# SAMA7G54D1G device description
Architecture: CORTEX-A7; Family: SAMA; Series: SAMA7G
Registers are 32-bit, read-write, reset 0x0 unless marked. A register's access mark holds for its fields unless they carry their own. Offsets are from the block's base; [hi:lo] are bit positions; lines under a group give offsets from that group; {n}, {i} and the like mark numbered series; 'fields as' and 'values as' point back to an identical list.

## PWM — Pulse Width Modulation Controller
Instances: PWM 0xE1604000
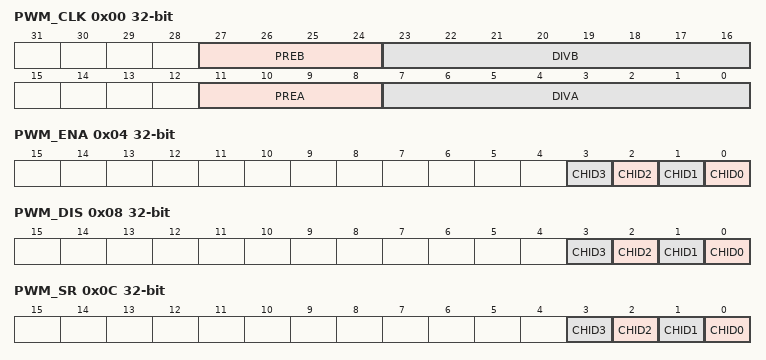
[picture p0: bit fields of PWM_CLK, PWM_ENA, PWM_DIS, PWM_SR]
0x00 PWM_CLK — PWM Clock Register
  [27:24] PREB — CLKB Source Clock Selection
    0=CLK (Peripheral clock); 1=CLK_DIV2 (Peripheral clock/2); 2=CLK_DIV4 (Peripheral clock/4); 3=CLK_DIV8 (Peripheral clock/8); 4=CLK_DIV16 (Peripheral clock/16); 5=CLK_DIV32 (Peripheral clock/32); 6=CLK_DIV64 (Peripheral clock/64); 7=CLK_DIV128 (Peripheral clock/128); 8=CLK_DIV256 (Peripheral clock/256); 9=CLK_DIV512 (Peripheral clock/512); 10=CLK_DIV1024 (Peripheral clock/1024)
  [23:16] DIVB — CLKB Divide Factor
    0=CLKB_POFF (CLKB clock is turned off); 1=PREB (CLKB clock is clock selected by PREB)
  [11:8] PREA — CLKA Source Clock Selection
    values as PREB
  [7:0] DIVA — CLKA Divide Factor
    0=CLKA_POFF (CLKA clock is turned off); 1=PREA (CLKA clock is clock selected by PREA)
0x04 PWM_ENA wo reset not defined — PWM Enable Register
  [all] fields
    0=No effect; 1=Enable PWM output for channel x
  [n] CHID{n} (n=0..3) — Channel ID
0x08 PWM_DIS wo reset not defined (atomic clear of PWM_SR) — PWM Disable Register
  [all] fields
    0=No effect; 1=Disable PWM output for channel x
  [n] CHID{n} (n=0..3) — Channel ID
0x0C PWM_SR ro — PWM Status Register
  [all] fields
    0=PWM output for channel x is disabled; 1=PWM output for channel x is enabled
  [n] CHID{n} (n=0..3) — Channel ID
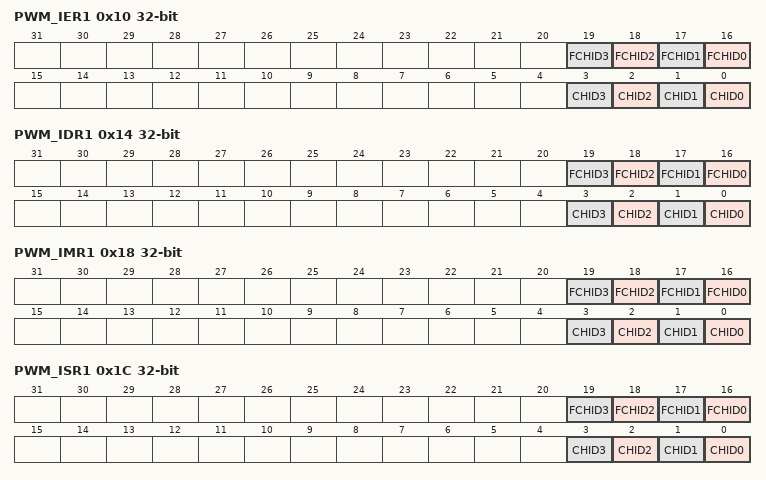
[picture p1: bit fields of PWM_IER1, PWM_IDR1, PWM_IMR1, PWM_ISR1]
0x10 PWM_IER1 wo reset not defined (atomic set of PWM_IMR1) — PWM Interrupt Enable Register 1
  [n+16] FCHID{n} (n=0..3) — Fault Protection Trigger on Channel {n} Interrupt Enable
  [n] CHID{n} (n=0..3) — Counter Event on Channel {n} Interrupt Enable
0x14 PWM_IDR1 wo reset not defined (atomic clear of PWM_IMR1) — PWM Interrupt Disable Register 1
  [n+16] FCHID{n} (n=0..3) — Fault Protection Trigger on Channel {n} Interrupt Disable
  [n] CHID{n} (n=0..3) — Counter Event on Channel {n} Interrupt Disable
0x18 PWM_IMR1 ro — PWM Interrupt Mask Register 1
  [n+16] FCHID{n} (n=0..3) — Fault Protection Trigger on Channel {n} Interrupt Mask
  [n] CHID{n} (n=0..3) — Counter Event on Channel {n} Interrupt Mask
0x1C PWM_ISR1 ro — PWM Interrupt Status Register 1
  [n+16] FCHID{n} (n=0..3) — Fault Protection Trigger on Channel {n}
    0=No new trigger of the fault protection since the last read of PWM_ISR1; 1=At least one trigger of the fault protection since the last read of PWM_ISR1
  [n] CHID{n} (n=0..3) — Counter Event on Channel {n}
    0=No new counter event has occurred since the last read of PWM_ISR1; 1=At least one counter event has occurred since the last read of PWM_ISR1
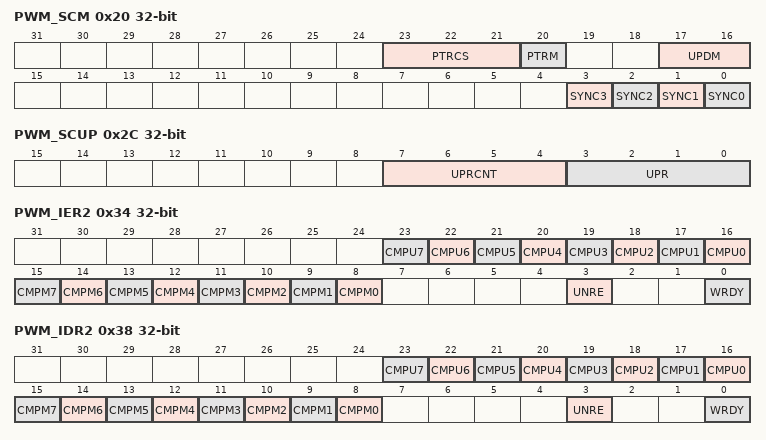
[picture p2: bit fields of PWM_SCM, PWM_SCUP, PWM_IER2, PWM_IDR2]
0x20 PWM_SCM — PWM Sync Channels Mode Register
  [23:21] PTRCS — DMA Controller Transfer Request Comparison Selection
  [20] PTRM — DMA Controller Transfer Request Mode
  [17:16] UPDM — Synchronous Channels Update Mode
    0=MODE0 (Manual write of double buffer registers and manual update of synchronous channels); 1=MODE1 (Manual write of double buffer registers and automatic update of synchronous channels); 2=MODE2 (Automatic write of duty-cycle update registers by the DMA Controller and automatic update of synchronous channels)
  [n] SYNC{n} (n=0..3) — Synchronous Channel {n}
    0=Channel x is not a synchronous channel; 1=Channel x is a synchronous channel
0x24 PWM_DMAR wo reset not defined — PWM DMA Register
  [23:0] DMADUTY — Duty-Cycle Holding Register for DMA Access
0x28 PWM_SCUC — PWM Sync Channels Update Control Register
  [0] UPDULOCK — Synchronous Channels Update Unlock
    0=No effect; 1=If the UPDM field is set to '0' in PWM Sync Channels Mode Register, writing the UPDULOCK bit to '1' triggers the update of the period value, the duty-cycle and the dead-time values of synchronous channels at the beginning of the next PWM period. If the field UPDM is set to '1' or '2', writing the UPDULOCK bit to '1' triggers only the update of the period value and of the dead-time values of synchronous channels.
0x2C PWM_SCUP — PWM Sync Channels Update Period Register
  [7:4] UPRCNT — Update Period Counter
  [3:0] UPR — Update Period
0x30 PWM_SCUPUPD wo reset not defined — PWM Sync Channels Update Period Update Register
  [3:0] UPRUPD — Update Period Update
0x34 PWM_IER2 wo reset not defined (atomic set of PWM_IMR2) — PWM Interrupt Enable Register 2
  [n+16] CMPU{n} (n=0..7) — Comparison {n} Update Interrupt Enable
  [n+8] CMPM{n} (n=0..7) — Comparison {n} Match Interrupt Enable
  [3] UNRE — Synchronous Channels Update Underrun Error Interrupt Enable
  [0] WRDY — Write Ready for Synchronous Channels Update Interrupt Enable
0x38 PWM_IDR2 wo reset not defined (atomic clear of PWM_IMR2) — PWM Interrupt Disable Register 2
  [n+16] CMPU{n} (n=0..7) — Comparison {n} Update Interrupt Disable
  [n+8] CMPM{n} (n=0..7) — Comparison {n} Match Interrupt Disable
  [3] UNRE — Synchronous Channels Update Underrun Error Interrupt Disable
  [0] WRDY — Write Ready for Synchronous Channels Update Interrupt Disable
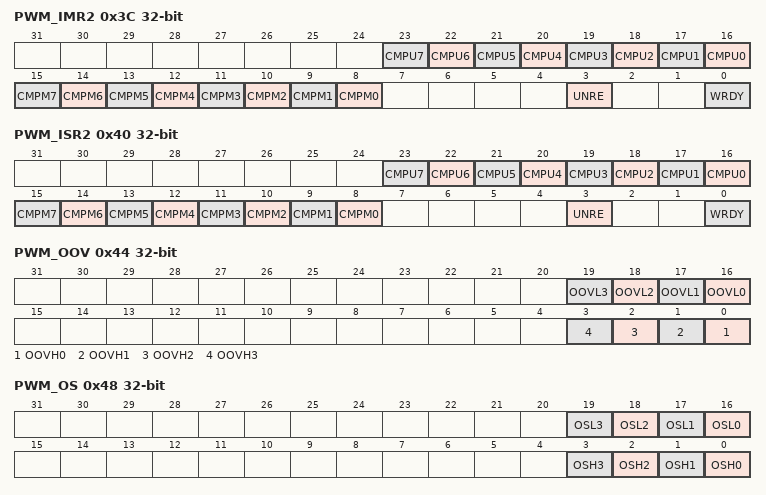
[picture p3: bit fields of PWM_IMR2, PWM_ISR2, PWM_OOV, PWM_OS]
0x3C PWM_IMR2 ro — PWM Interrupt Mask Register 2
  [n+16] CMPU{n} (n=0..7) — Comparison {n} Update Interrupt Mask
  [n+8] CMPM{n} (n=0..7) — Comparison {n} Match Interrupt Mask
  [3] UNRE — Synchronous Channels Update Underrun Error Interrupt Mask
  [0] WRDY — Write Ready for Synchronous Channels Update Interrupt Mask
0x40 PWM_ISR2 ro — PWM Interrupt Status Register 2
  [n+16] CMPU{n} (n=0..7) — Comparison {n} Update
    0=The comparison x has not been updated since the last read of the PWM_ISR2 register; 1=The comparison x has been updated at least one time since the last read of the PWM_ISR2 register
  [n+8] CMPM{n} (n=0..7) — Comparison {n} Match
    0=The comparison x has not matched since the last read of the PWM_ISR2 register; 1=The comparison x has matched at least one time since the last read of the PWM_ISR2 register
  [3] UNRE — Synchronous Channels Update Underrun Error
    0=No Synchronous Channels Update Underrun has occurred since the last read of the PWM_ISR2 register; 1=At least one Synchronous Channels Update Underrun has occurred since the last read of the PWM_ISR2 register
  [0] WRDY — Write Ready for Synchronous Channels Update
    0=New duty-cycle and dead-time values for the synchronous channels cannot be written; 1=New duty-cycle and dead-time values for the synchronous channels can be written
0x44 PWM_OOV — PWM Output Override Value Register
  [n+16] OOVL{n} (n=0..3) — Output Override Value for PWML output of the channel {n}
    0=Override value is 0 for PWML output of channel x; 1=Override value is 1 for PWML output of channel x
  [n] OOVH{n} (n=0..3) — Output Override Value for PWMH output of the channel {n}
    0=Override value is 0 for PWMH output of channel x; 1=Override value is 1 for PWMH output of channel x
0x48 PWM_OS — PWM Output Selection Register
  [n+16] OSL{n} (n=0..3) — Output Selection for PWML output of the channel {n}
    0=Dead-time generator output DTOLx selected as PWML output of channel x; 1=Output override value OOVLx selected as PWML output of channel x
  [n] OSH{n} (n=0..3) — Output Selection for PWMH output of the channel {n}
    0=Dead-time generator output DTOHx selected as PWMH output of channel x; 1=Output override value OOVHx selected as PWMH output of channel x
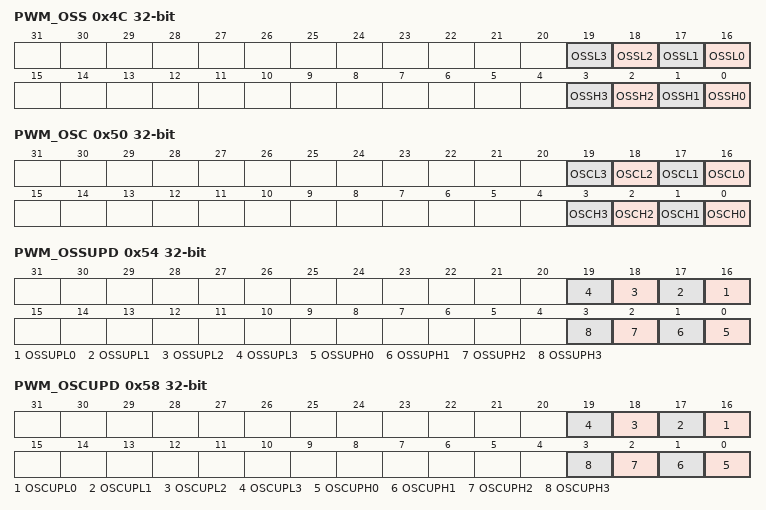
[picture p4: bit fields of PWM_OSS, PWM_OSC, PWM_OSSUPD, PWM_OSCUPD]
0x4C PWM_OSS wo reset not defined — PWM Output Selection Set Register
  [n+16] OSSL{n} (n=0..3) — Output Selection Set for PWML output of the channel {n}
    0=No effect; 1=Output override value OOVLx selected as PWML output of channel x
  [n] OSSH{n} (n=0..3) — Output Selection Set for PWMH output of the channel {n}
    0=No effect; 1=Output override value OOVHx selected as PWMH output of channel x
0x50 PWM_OSC wo reset not defined — PWM Output Selection Clear Register
  [n+16] OSCL{n} (n=0..3) — Output Selection Clear for PWML output of the channel {n}
    0=No effect; 1=Dead-time generator output DTOLx selected as PWML output of channel x
  [n] OSCH{n} (n=0..3) — Output Selection Clear for PWMH output of the channel {n}
    0=No effect; 1=Dead-time generator output DTOHx selected as PWMH output of channel x
0x54 PWM_OSSUPD wo reset not defined — PWM Output Selection Set Update Register
  [n+16] OSSUPL{n} (n=0..3) — Output Selection Set for PWML output of the channel {n}
    0=No effect; 1=Output override value OOVLx selected as PWML output of channel x at the beginning of the next channel x PWM period
  [n] OSSUPH{n} (n=0..3) — Output Selection Set for PWMH output of the channel {n}
    0=No effect; 1=Output override value OOVHx selected as PWMH output of channel x at the beginning of the next channel x PWM period
0x58 PWM_OSCUPD wo reset not defined — PWM Output Selection Clear Update Register
  [n+16] OSCUPL{n} (n=0..3) — Output Selection Clear for PWML output of the channel {n}
    0=No effect; 1=Dead-time generator output DTOLx selected as PWML output of channel x at the beginning of the next channel x PWM period
  [n] OSCUPH{n} (n=0..3) — Output Selection Clear for PWMH output of the channel {n}
    0=No effect; 1=Dead-time generator output DTOHx selected as PWMH output of channel x at the beginning of the next channel x PWM period
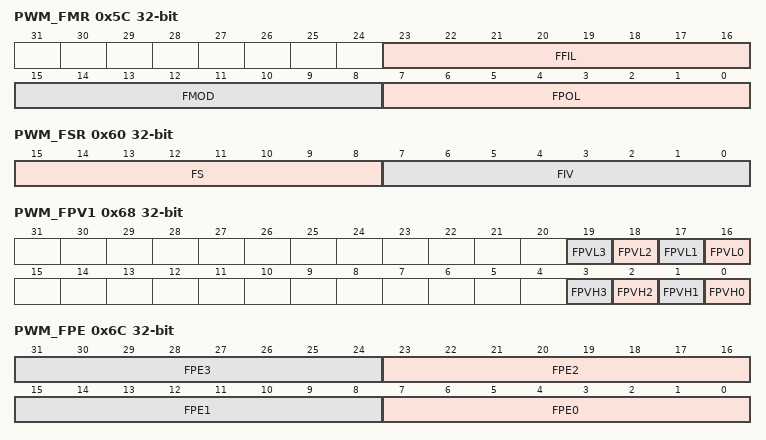
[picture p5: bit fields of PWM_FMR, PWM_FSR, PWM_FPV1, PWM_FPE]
0x5C PWM_FMR — PWM Fault Mode Register
  [23:16] FFIL — Fault Filtering
  [15:8] FMOD — Fault Activation Mode
  [7:0] FPOL — Fault Polarity
    0=The fault y becomes active when the fault input y is at 0; 1=The fault y becomes active when the fault input y is at 1
0x60 PWM_FSR ro — PWM Fault Status Register
  [15:8] FS — Fault Status
  [7:0] FIV — Fault Input Value
0x64 PWM_FCR wo reset not defined — PWM Fault Clear Register
  [7:0] FCLR — Fault Clear
0x68 PWM_FPV1 — PWM Fault Protection Value Register 1
  [n+16] FPVL{n} (n=0..3) — Fault Protection Value for PWML output on channel {n}
    0=PWML output of channel x is forced to '0' when fault occurs; 1=PWML output of channel x is forced to '1' when fault occurs
  [n] FPVH{n} (n=0..3) — Fault Protection Value for PWMH output on channel {n}
    0=PWMH output of channel x is forced to '0' when fault occurs; 1=PWMH output of channel x is forced to '1' when fault occurs
0x6C PWM_FPE — PWM Fault Protection Enable Register
  [8n+7:8n] FPE{n} (n=0..3) — Fault Protection Enable for channel {n}
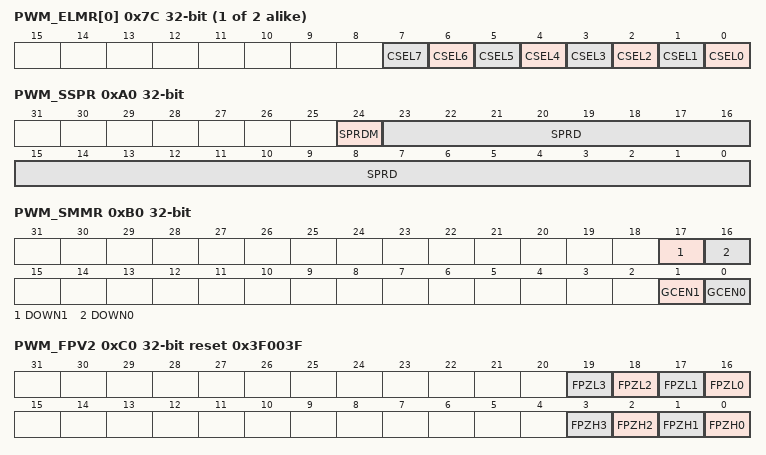
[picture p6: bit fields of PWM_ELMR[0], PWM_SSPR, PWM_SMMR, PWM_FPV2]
{0x7C+4i} PWM_ELMR[{i}] (i=0..1) — PWM Event Line x Mode Register
  [all] fields
    0=A pulse is not generated on the event line x when the comparison y matches; 1=A pulse is generated on the event line x when the comparison y match
  [n] CSEL{n} (n=0..7) — Comparison y Selection
0xA0 PWM_SSPR — PWM Spread Spectrum Register
  [24] SPRDM — Spread Spectrum Counter Mode
    0=Triangular mode. The spread spectrum counter starts to count from -SPRD when the channel 0 is enabled and counts upwards at each PWM period. When it reaches +SPRD, it restarts to count from -SPRD again.; 1=Random mode. The spread spectrum counter is loaded with a new random value at each PWM period. This random value is uniformly distributed and is between -SPRD and +SPRD.
  [23:0] SPRD — Spread Spectrum Limit Value
0xA4 PWM_SSPUP wo reset not defined — PWM Spread Spectrum Update Register
  [23:0] SPRDUP — Spread Spectrum Limit Value Update
0xB0 PWM_SMMR — PWM Stepper Motor Mode Register
  [17] DOWN1 — Down Count
    0=Up counter; 1=Down counter
  [16] DOWN0 — Down Count
    0=Up counter; 1=Down counter
  [1] GCEN1 — Gray Count Enable
    0=Disable Gray count generation on PWML[2*x], PWMH[2*x], PWML[2*x +1], PWMH[2*x +1]; 1=Enable Gray count generation on PWML[2*x], PWMH[2*x], PWML[2*x +1], PWMH[2*x +1]
  [0] GCEN0 — Gray Count Enable
    values as GCEN1
0xC0 PWM_FPV2 reset 0x3F003F — PWM Fault Protection Value 2 Register
  [n+16] FPZL{n} (n=0..3) — Fault Protection to Hi-Z for PWML output on channel {n}
    0=When fault occurs, PWML output of channel x is forced to value defined by the bit FPVLx in PWM Fault Protection Value Register 1; 1=When fault occurs, PWML output of channel x is forced to high-impedance state
  [n] FPZH{n} (n=0..3) — Fault Protection to Hi-Z for PWMH output on channel {n}
    0=When fault occurs, PWMH output of channel x is forced to value defined by the bit FPVHx in PWM Fault Protection Value Register 1; 1=When fault occurs, PWMH output of channel x is forced to high-impedance state
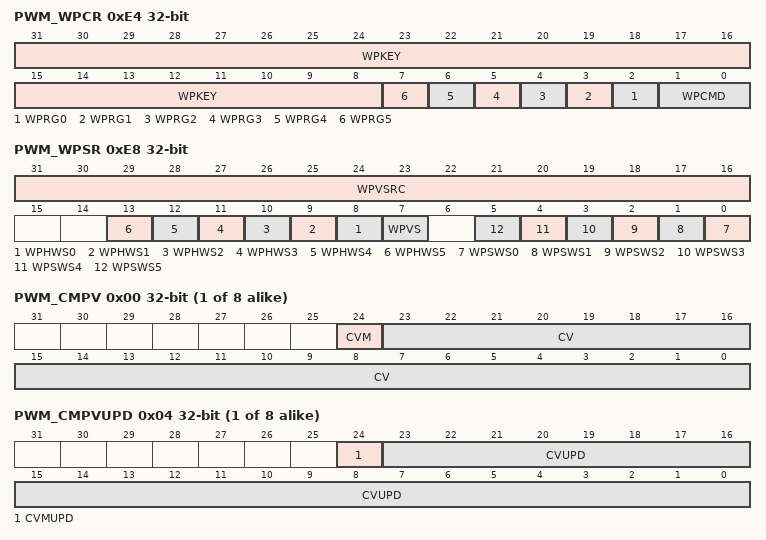
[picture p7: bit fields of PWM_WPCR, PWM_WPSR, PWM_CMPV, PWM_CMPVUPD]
0xE4 PWM_WPCR wo reset not defined — PWM Write Protection Control Register
  [31:8] WPKEY — Write Protection Key
    0x50574D=PASSWD (Writing any other value in this field aborts the write operation of the WPCMD field. Always reads as 0)
  [n+2] WPRG{n} (n=0..5) — Write Protection Register Group {n}
    0=The WPCMD command has no effect on the register group x; 1=The WPCMD command is applied to the register group x
  [1:0] WPCMD — Write Protection Command
    0=DISABLE_SW_PROT (Disables the software write protection of the register groups of which the bit WPRGx is at '1'.); 1=ENABLE_SW_PROT (Enables the software write protection of the register groups of which the bit WPRGx is at '1'.); 2=ENABLE_HW_PROT (Enables the hardware write protection of the register groups of which the bit WPRGx is at '1'. Only a hardware reset of the PWM controller can disable the hardware write protection. Moreover, to meet security requirements, the PIO lines associated with the PWM can not be configured through the PIO interface.)
0xE8 PWM_WPSR ro — PWM Write Protection Status Register
  [31:16] WPVSRC — Write Protect Violation Source
  [n+8] WPHWS{n} (n=0..5) — Write Protect HW Status
    0=The HW write protection x of the register group x is disabled; 1=The HW write protection x of the register group x is enabled
  [7] WPVS — Write Protect Violation Status
    0=No write protection violation has occurred since the last read of PWM_WPSR; 1=At least one write protection violation has occurred since the last read of PWM_WPSR. If this violation is an unauthorized attempt to write a protected register, the associated violation is reported into field WPVSRC.
  [n] WPSWS{n} (n=0..5) — Write Protect SW Status
    0=The SW write protection x of the register group x is disabled; 1=The SW write protection x of the register group x is enabled
{0x130+0x10*i} PWM_CMP[{i}] (i=0..7) group
  0x00 PWM_CMPV — PWM Comparison x Value Register
    [24] CVM — Comparison Value Mode
      0=The comparison x between the counter of the channel 0 and the comparison x value is performed when this counter is incrementing; 1=The comparison x between the counter of the channel 0 and the comparison x value is performed when this counter is decrementing
    [23:0] CV — Comparison Value
  0x04 PWM_CMPVUPD wo reset not defined — PWM Comparison x Value Update Register
    [24] CVMUPD — Comparison Value Mode Update
      values as PWM_CMP[0].PWM_CMPV.CVM
    [23:0] CVUPD — Comparison Value Update
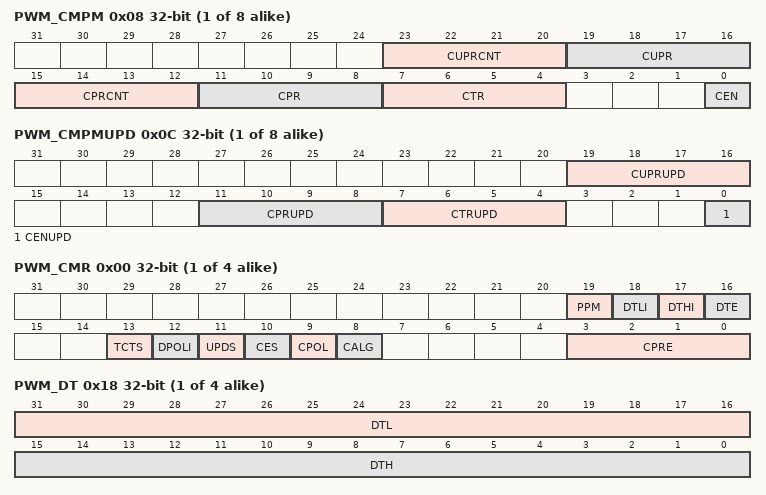
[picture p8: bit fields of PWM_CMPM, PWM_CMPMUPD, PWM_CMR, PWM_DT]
  0x08 PWM_CMPM — PWM Comparison x Mode Register
    [23:20] CUPRCNT — Comparison Update Period Counter
    [19:16] CUPR — Comparison Update Period
    [15:12] CPRCNT — Comparison Period Counter
    [11:8] CPR — Comparison Period
    [7:4] CTR — Comparison Trigger
    [0] CEN — Comparison Enable
      0=The comparison x is disabled and can not match; 1=The comparison x is enabled and can match
  0x0C PWM_CMPMUPD wo reset not defined — PWM Comparison x Mode Update Register
    [19:16] CUPRUPD — Comparison Update Period Update
    [11:8] CPRUPD — Comparison Period Update
    [7:4] CTRUPD — Comparison Trigger Update
    [0] CENUPD — Comparison Enable Update
      values as PWM_CMP[0].PWM_CMPM.CEN
{0x200+0x20*i} PWM_CH_NUM[{i}] (i=0..3) group
  0x00 PWM_CMR — PWM Channel Mode Register
    [19] PPM — Push-Pull Mode
      0=The Push-Pull mode is disabled for channel x; 1=The Push-Pull mode is enabled for channel x
    [18] DTLI — Dead-Time PWMLx Output Inverted
      0=The dead-time PWMLx output is not inverted; 1=The dead-time PWMLx output is inverted
    [17] DTHI — Dead-Time PWMHx Output Inverted
      0=The dead-time PWMHx output is not inverted; 1=The dead-time PWMHx output is inverted
    [16] DTE — Dead-Time Generator Enable
      0=The dead-time generator is disabled; 1=The dead-time generator is enabled
    [13] TCTS — Timer Counter Trigger Selection
      0=The comparator of the channel x (OCx) is used as the trigger source for the Timer Counter (TC); 1=The counter events of the channel x is used as the trigger source for the Timer Counter (TC)
    [12] DPOLI — Disabled Polarity Inverted
      0=When the PWM channel x is disabled (CHIDx(PWM_SR) = 0), the OCx output waveform is the same as the one defined by the CPOL bit; 1=When the PWM channel x is disabled (CHIDx(PWM_SR) = 0), the OCx output waveform is inverted compared to the one defined by the CPOL bit
    [11] UPDS — Update Selection
      0=The update occurs at the next end of the PWM period after writing the update register(s); 1=The update occurs at the next end of the PWM half period after writing the update register(s)
    [10] CES — Counter Event Selection
      0=The channel counter event occurs at the end of the PWM period; 1=The channel counter event occurs at the end of the PWM period and at half the PWM period
    [9] CPOL — Channel Polarity
      0=The OCx output waveform (output from the comparator) starts at a low level; 1=The OCx output waveform (output from the comparator) starts at a high level
    [8] CALG — Channel Alignment
      0=The period is left-aligned; 1=The period is center-aligned
    [3:0] CPRE — Channel Prescaler
      0=MCK (Peripheral clock); 1=MCK_DIV_2 (Peripheral clock/2); 2=MCK_DIV_4 (Peripheral clock/4); 3=MCK_DIV_8 (Peripheral clock/8); 4=MCK_DIV_16 (Peripheral clock/16); 5=MCK_DIV_32 (Peripheral clock/32); 6=MCK_DIV_64 (Peripheral clock/64); 7=MCK_DIV_128 (Peripheral clock/128); 8=MCK_DIV_256 (Peripheral clock/256); 9=MCK_DIV_512 (Peripheral clock/512); 10=MCK_DIV_1024 (Peripheral clock/1024); 11=CLKA (Clock A); 12=CLKB (Clock B)
  0x04 PWM_CDTY — PWM Channel Duty Cycle Register
    [23:0] CDTY — Channel Duty-Cycle
  0x08 PWM_CDTYUPD wo reset not defined — PWM Channel Duty Cycle Update Register
    [23:0] CDTYUPD — Channel Duty-Cycle Update
  0x0C PWM_CPRD — PWM Channel Period Register
    [23:0] CPRD — Channel Period
  0x10 PWM_CPRDUPD wo reset not defined — PWM Channel Period Update Register
    [23:0] CPRDUPD — Channel Period Update
  0x14 PWM_CCNT ro — PWM Channel Counter Register
    [23:0] CNT — Channel Counter Register
  0x18 PWM_DT — PWM Channel Dead Time Register
    [31:16] DTL — Dead-Time Value for PWMLx Output
    [15:0] DTH — Dead-Time Value for PWMHx Output
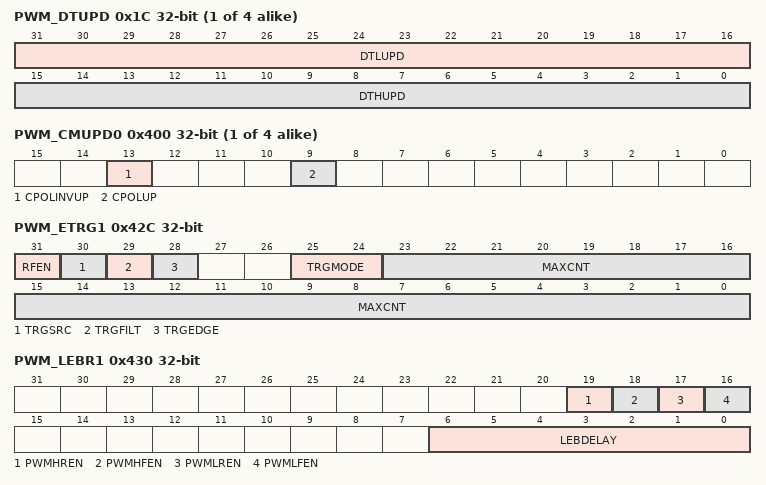
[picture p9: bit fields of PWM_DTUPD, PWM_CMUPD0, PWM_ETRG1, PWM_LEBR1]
  0x1C PWM_DTUPD wo reset not defined — PWM Channel Dead Time Update Register
    [31:16] DTLUPD — Dead-Time Value Update for PWMLx Output
    [15:0] DTHUPD — Dead-Time Value Update for PWMHx Output
{0x400+0x20*i} PWM_CMUPD{i} wo reset not defined (i=0..3) — PWM Channel Mode Update Register (ch_num = {i})
  [13] CPOLINVUP — Channel Polarity Inversion Update
    0=No effect; 1=The OCx output waveform (output from the comparator) is inverted
  [9] CPOLUP — Channel Polarity Update
    values as PWM_CH_NUM[0].PWM_CMR.CPOL
0x42C PWM_ETRG1 reset not defined — PWM External Trigger Register 1
  [31] RFEN — Recoverable Fault Enable
    0=The TRGINx signal does not generate a recoverable fault; 1=The TRGINx signal generate a recoverable fault in place of the fault x input
  [30] TRGSRC — Trigger Source
    0=The TRGINx signal is driven by the PWMEXTRGx input; 1=The TRGINx signal is driven by the Analog Comparator Controller
  [29] TRGFILT — Filtered input
    0=The external trigger input x is not filtered; 1=The external trigger input x is filtered
  [28] TRGEDGE — Edge Selection
    0=FALLING_ZERO (TRGMODE = 1: TRGINx event detection on falling edge. TRGMODE = 2, 3: TRGINx active level is 0); 1=RISING_ONE (TRGMODE = 1: TRGINx event detection on rising edge. TRGMODE = 2, 3: TRGINx active level is 1)
  [25:24] TRGMODE — External Trigger Mode
    0=OFF (External trigger is not enabled.); 1=MODE1 (External PWM Reset Mode); 2=MODE2 (External PWM Start Mode); 3=MODE3 (Cycle-by-cycle Duty Mode)
  [23:0] MAXCNT — Maximum Counter value
0x430 PWM_LEBR1 reset not defined — PWM Leading-Edge Blanking Register 1
  [19] PWMHREN — PWMH Rising Edge Enable
    0=Leading-edge blanking is disabled on PWMHx output rising edge; 1=Leading-edge blanking is enabled on PWMHx output rising edge
  [18] PWMHFEN — PWMH Falling Edge Enable
    0=Leading-edge blanking is disabled on PWMHx output falling edge; 1=Leading-edge blanking is enabled on PWMHx output falling edge
  [17] PWMLREN — PWML Rising Edge Enable
    0=Leading-edge blanking is disabled on PWMLx output rising edge; 1=Leading-edge blanking is enabled on PWMLx output rising edge
  [16] PWMLFEN — PWML Falling Edge Enable
    0=Leading-edge blanking is disabled on PWMLx output falling edge; 1=Leading-edge blanking is enabled on PWMLx output falling edge
  [6:0] LEBDELAY — Leading-Edge Blanking Delay for TRGINx
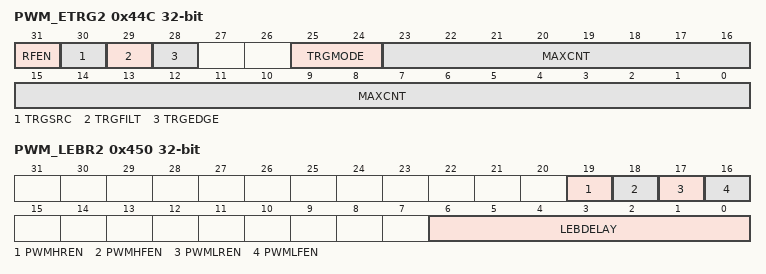
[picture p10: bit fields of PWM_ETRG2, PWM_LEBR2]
0x44C PWM_ETRG2 reset not defined — PWM External Trigger Register 2
  fields as PWM_ETRG1
0x450 PWM_LEBR2 reset not defined — PWM Leading-Edge Blanking Register 2
  fields as PWM_LEBR1
